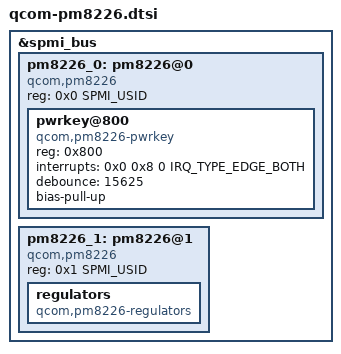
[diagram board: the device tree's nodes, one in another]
// SPDX-License-Identifier: GPL-2.0
#include <dt-bindings/iio/qcom,spmi-vadc.h>
#include <dt-bindings/interrupt-controller/irq.h>
#include <dt-bindings/spmi/spmi.h>

&spmi_bus {

	pm8226_0: pm8226@0 {
		compatible = "qcom,pm8226", "qcom,spmi-pmic";
		reg = <0x0 SPMI_USID>;
		#address-cells = <1>;
		#size-cells = <0>;

		pwrkey@800 {
			compatible = "qcom,pm8226-pwrkey", "qcom,pm8941-pwrkey";
			reg = <0x800>;
			interrupts = <0x0 0x8 0 IRQ_TYPE_EDGE_BOTH>;
			debounce = <15625>;
			bias-pull-up;
		};
	};

	pm8226_1: pm8226@1 {
		compatible = "qcom,pm8226", "qcom,spmi-pmic";
		reg = <0x1 SPMI_USID>;
		#address-cells = <1>;
		#size-cells = <0>;

		regulators {
			compatible = "qcom,pm8226-regulators";
			//interrupts = <0x1 0x83 0x2 0>, <0x1 0x84 0x2 0>;
			//interrupt-names = "ocp-5vs1", "ocp-5vs2";
			//vin_5vs-supply = <&pm8941_5v>;
		};
	};

};
